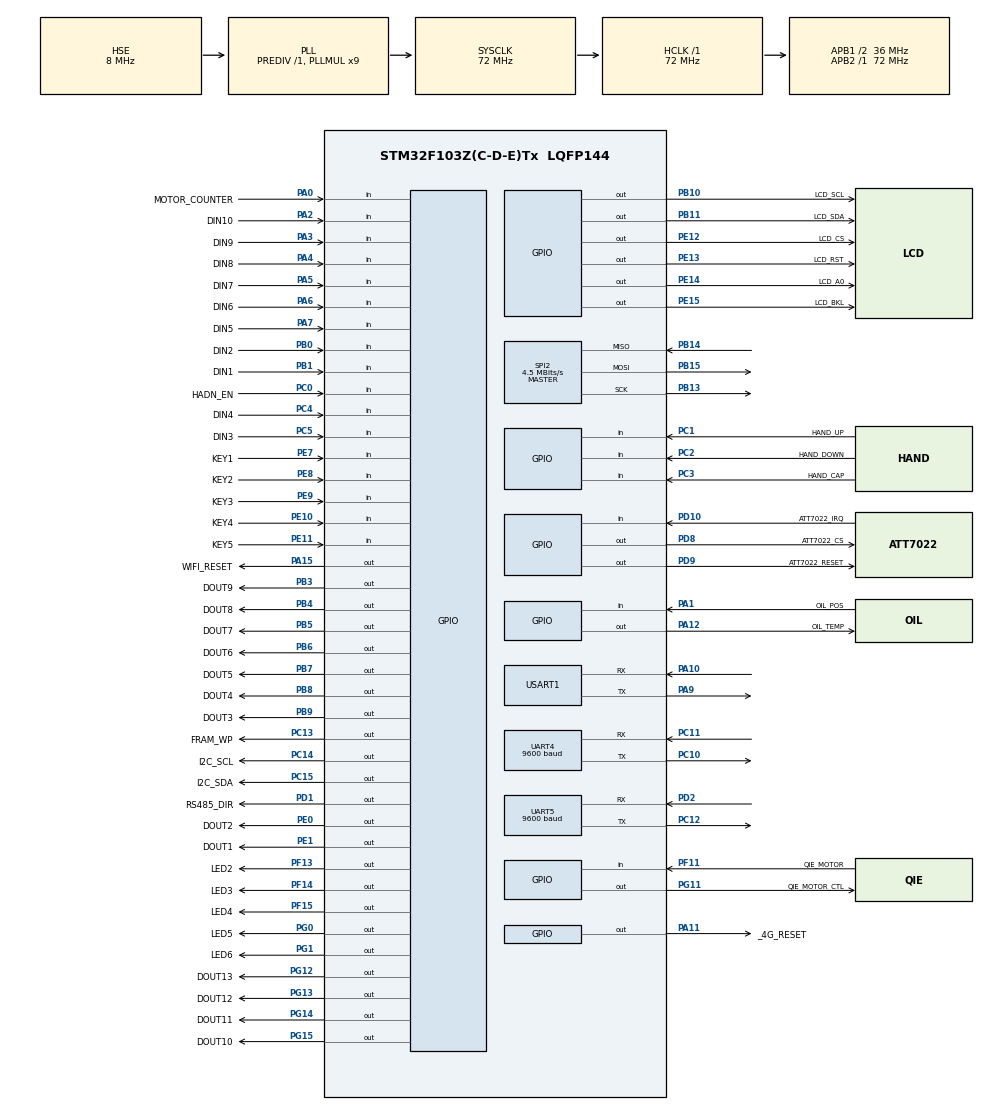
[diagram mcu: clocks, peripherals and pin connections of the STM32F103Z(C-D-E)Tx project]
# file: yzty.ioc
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IWDG.Prescaler=IWDG_PRESCALER_256
Mcu.Family=STM32F1
Mcu.Name=STM32F103Z(C-D-E)Tx
Mcu.Package=LQFP144
NVIC.PriorityGroup=NVIC_PRIORITYGROUP_4
NVIC.UART4_IRQn=true\:0\:0\:false\:false\:true\:true\:true
NVIC.UART5_IRQn=true\:0\:0\:false\:false\:true\:true\:true
NVIC.USART1_IRQn=true\:0\:0\:false\:false\:true\:true\:true
OSC_IN.Mode=HSE-External-Oscillator
OSC_IN.Signal=RCC_OSC_IN
OSC_OUT.Mode=HSE-External-Oscillator
OSC_OUT.Signal=RCC_OSC_OUT
PA0-WKUP.GPIO_Label=MOTOR_COUNTER
PA0-WKUP.Signal=GPIO_Input
PA1.GPIO_Label=OIL_POS
PA1.GPIO_PuPd=GPIO_PULLUP
PA1.Signal=GPIO_Input
PA10.Mode=Asynchronous
PA10.Signal=USART1_RX
PA11.GPIO_Label=_4G_RESET
PA11.PinState=GPIO_PIN_SET
PA11.Signal=GPIO_Output
PA12.GPIO_Label=OIL_TEMP
PA12.GPIO_ModeDefaultOutputPP=GPIO_MODE_OUTPUT_OD
PA12.GPIO_Speed=GPIO_SPEED_FREQ_HIGH
PA12.PinState=GPIO_PIN_SET
PA12.Signal=GPIO_Output
PA13.Mode=Serial_Wire
PA13.Signal=SYS_JTMS-SWDIO
PA14.Mode=Serial_Wire
PA14.Signal=SYS_JTCK-SWCLK
PA15.GPIO_Label=WIFI_RESET
PA15.PinState=GPIO_PIN_SET
PA15.Signal=GPIO_Output
PA2.GPIO_Label=DIN10
PA2.GPIO_PuPd=GPIO_PULLUP
PA2.Signal=GPIO_Input
PA3.GPIO_Label=DIN9
PA3.GPIO_PuPd=GPIO_PULLUP
PA3.Signal=GPIO_Input
PA4.GPIO_Label=DIN8
PA4.GPIO_PuPd=GPIO_PULLUP
PA4.Signal=GPIO_Input
PA5.GPIO_Label=DIN7
PA5.GPIO_PuPd=GPIO_PULLUP
PA5.Signal=GPIO_Input
PA6.GPIO_Label=DIN6
PA6.GPIO_PuPd=GPIO_PULLUP
PA6.Signal=GPIO_Input
PA7.GPIO_Label=DIN5
PA7.GPIO_PuPd=GPIO_PULLUP
PA7.Signal=GPIO_Input
PA9.Mode=Asynchronous
PA9.Signal=USART1_TX
PB0.GPIO_Label=DIN2
PB0.GPIO_PuPd=GPIO_PULLUP
PB0.Signal=GPIO_Input
PB1.GPIO_Label=DIN1
PB1.GPIO_PuPd=GPIO_PULLUP
PB1.Signal=GPIO_Input
PB10.GPIO_Label=LCD_SCL
PB10.GPIO_Speed=GPIO_SPEED_FREQ_HIGH
PB10.PinState=GPIO_PIN_SET
PB10.Signal=GPIO_Output
PB11.GPIO_Label=LCD_SDA
PB11.GPIO_Speed=GPIO_SPEED_FREQ_HIGH
PB11.PinState=GPIO_PIN_SET
PB11.Signal=GPIO_Output
PB13.Mode=Full_Duplex_Master
PB13.Signal=SPI2_SCK
PB14.Mode=Full_Duplex_Master
PB14.Signal=SPI2_MISO
PB15.Mode=Full_Duplex_Master
PB15.Signal=SPI2_MOSI
PB3.GPIO_Label=DOUT9
PB3.PinState=GPIO_PIN_SET
PB3.Signal=GPIO_Output
PB4.GPIO_Label=DOUT8
PB4.PinState=GPIO_PIN_RESET
PB4.Signal=GPIO_Output
PB5.GPIO_Label=DOUT7
PB5.PinState=GPIO_PIN_SET
PB5.Signal=GPIO_Output
PB6.GPIO_Label=DOUT6
PB6.PinState=GPIO_PIN_SET
PB6.Signal=GPIO_Output
PB7.GPIO_Label=DOUT5
PB7.PinState=GPIO_PIN_SET
PB7.Signal=GPIO_Output
PB8.GPIO_Label=DOUT4
PB8.PinState=GPIO_PIN_SET
PB8.Signal=GPIO_Output
PB9.GPIO_Label=DOUT3
PB9.PinState=GPIO_PIN_SET
PB9.Signal=GPIO_Output
PC0.GPIO_Label=HADN_EN
PC0.Signal=GPIO_Input
PC1.GPIO_Label=HAND_UP
PC1.Signal=GPIO_Input
PC10.Mode=Asynchronous
PC10.Signal=UART4_TX
PC11.Mode=Asynchronous
PC11.Signal=UART4_RX
PC12.Mode=Asynchronous
PC12.Signal=UART5_TX
PC13-TAMPER-RTC.GPIO_Label=FRAM_WP
PC13-TAMPER-RTC.PinState=GPIO_PIN_SET
PC13-TAMPER-RTC.Signal=GPIO_Output
PC14-OSC32_IN.GPIO_Label=I2C_SCL
PC14-OSC32_IN.GPIO_ModeDefaultOutputPP=GPIO_MODE_OUTPUT_OD
PC14-OSC32_IN.GPIO_Speed=GPIO_SPEED_FREQ_HIGH
PC14-OSC32_IN.PinState=GPIO_PIN_SET
PC14-OSC32_IN.Signal=GPIO_Output
PC15-OSC32_OUT.GPIO_Label=I2C_SDA
PC15-OSC32_OUT.GPIO_ModeDefaultOutputPP=GPIO_MODE_OUTPUT_OD
PC15-OSC32_OUT.GPIO_Speed=GPIO_SPEED_FREQ_HIGH
PC15-OSC32_OUT.PinState=GPIO_PIN_SET
PC15-OSC32_OUT.Signal=GPIO_Output
PC2.GPIO_Label=HAND_DOWN
PC2.Signal=GPIO_Input
PC3.GPIO_Label=HAND_CAP
PC3.Signal=GPIO_Input
PC4.GPIO_Label=DIN4
PC4.GPIO_PuPd=GPIO_PULLUP
PC4.Signal=GPIO_Input
PC5.GPIO_Label=DIN3
PC5.GPIO_PuPd=GPIO_PULLUP
PC5.Signal=GPIO_Input
PD1.GPIO_Label=RS485_DIR
PD1.PinState=GPIO_PIN_SET
PD1.Signal=GPIO_Output
PD10.GPIO_Label=ATT7022_IRQ
PD10.Signal=GPIO_Input
PD2.Mode=Asynchronous
PD2.Signal=UART5_RX
PD8.GPIO_Label=ATT7022_CS
PD8.PinState=GPIO_PIN_SET
PD8.Signal=GPIO_Output
PD9.GPIO_Label=ATT7022_RESET
PD9.PinState=GPIO_PIN_SET
PD9.Signal=GPIO_Output
PE0.GPIO_Label=DOUT2
PE0.PinState=GPIO_PIN_SET
PE0.Signal=GPIO_Output
PE1.GPIO_Label=DOUT1
PE1.GPIO_Speed=GPIO_SPEED_FREQ_LOW
PE1.PinState=GPIO_PIN_SET
PE1.Signal=GPIO_Output
PE10.GPIO_Label=KEY4
PE10.Signal=GPIO_Input
PE11.GPIO_Label=KEY5
PE11.Signal=GPIO_Input
PE12.GPIO_Label=LCD_CS
PE12.PinState=GPIO_PIN_SET
PE12.Signal=GPIO_Output
PE13.GPIO_Label=LCD_RST
PE13.PinState=GPIO_PIN_SET
PE13.Signal=GPIO_Output
PE14.GPIO_Label=LCD_A0
PE14.PinState=GPIO_PIN_SET
PE14.Signal=GPIO_Output
PE15.GPIO_Label=LCD_BKL
PE15.PinState=GPIO_PIN_SET
PE15.Signal=GPIO_Output
PE7.GPIO_Label=KEY1
PE7.Signal=GPIO_Input
PE8.GPIO_Label=KEY2
PE8.Signal=GPIO_Input
PE9.GPIO_Label=KEY3
PE9.Signal=GPIO_Input
PF11.GPIO_Label=QIE_MOTOR
PF11.Signal=GPIO_Input
PF13.GPIO_Label=LED2
PF13.PinState=GPIO_PIN_SET
PF13.Signal=GPIO_Output
PF14.GPIO_Label=LED3
PF14.PinState=GPIO_PIN_SET
PF14.Signal=GPIO_Output
PF15.GPIO_Label=LED4
PF15.PinState=GPIO_PIN_SET
PF15.Signal=GPIO_Output
PG0.GPIO_Label=LED5
PG0.PinState=GPIO_PIN_SET
PG0.Signal=GPIO_Output
PG1.GPIO_Label=LED6
PG1.PinState=GPIO_PIN_SET
PG1.Signal=GPIO_Output
PG11.GPIO_Label=QIE_MOTOR_CTL
PG11.Signal=GPIO_Output
PG12.GPIO_Label=DOUT13
PG12.PinState=GPIO_PIN_SET
PG12.Signal=GPIO_Output
PG13.GPIO_Label=DOUT12
PG13.PinState=GPIO_PIN_SET
PG13.Signal=GPIO_Output
PG14.GPIO_Label=DOUT11
PG14.PinState=GPIO_PIN_SET
PG14.Signal=GPIO_Output
PG15.GPIO_Label=DOUT10
PG15.PinState=GPIO_PIN_SET
PG15.Signal=GPIO_Output
ProjectManager.HeapSize=0x200
ProjectManager.StackSize=0x400
ProjectManager.TargetToolchain=MDK-ARM V5
RCC.AHBFreq_Value=72000000
RCC.APB1CLKDivider=RCC_HCLK_DIV2
RCC.APB1Freq_Value=36000000
RCC.APB1TimFreq_Value=72000000
RCC.APB2Freq_Value=72000000
RCC.APB2TimFreq_Value=72000000
RCC.HCLKFreq_Value=72000000
RCC.PLLMUL=RCC_PLL_MUL9
RCC.PLLSourceVirtual=RCC_PLLSOURCE_HSE
RCC.SYSCLKFreq_VALUE=72000000
RCC.SYSCLKSource=RCC_SYSCLKSOURCE_PLLCLK
RCC.USBFreq_Value=72000000
SPI2.BaudRatePrescaler=SPI_BAUDRATEPRESCALER_8
SPI2.CLKPhase=SPI_PHASE_2EDGE
SPI2.CalculateBaudRate=4.5 MBits/s
SPI2.Direction=SPI_DIRECTION_2LINES
SPI2.Mode=SPI_MODE_MASTER
SPI2.VirtualType=VM_MASTER
UART4.BaudRate=9600
UART4.VirtualMode=Asynchronous
UART5.BaudRate=9600
UART5.VirtualMode=Asynchronous
USART1.VirtualMode=VM_ASYNC
VP_IWDG_VS_IWDG.Mode=IWDG_Activate
board=custom

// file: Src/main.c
/* USER CODE BEGIN Header */
/**
  ******************************************************************************
  * @file           : main.c
  * @brief          : Main program body
  ******************************************************************************
  * @attention
  *
  * <h2><center>&copy; Copyright (c) 2019 STMicroelectronics.
  * All rights reserved.</center></h2>
  *
  * This software component is licensed by ST under BSD 3-Clause license,
  * the "License"; You may not use this file except in compliance with the
  * License. You may obtain a copy of the License at:
  *                        opensource.org/licenses/BSD-3-Clause
  *
  ******************************************************************************
  */
/* USER CODE END Header */

#include "main.h"
#include "iwdg.h"
#include "spi.h"
#include "usart.h"
#include "gpio.h"

/* USER CODE BEGIN Includes */
#include "task.h"
#include "debug.h"
/* USER CODE END Includes */

void SystemClock_Config(void);

int main(void)
{

  /* MCU Configuration--------------------------------------------------------*/

  /* Reset of all peripherals, Initializes the Flash interface and the Systick. */
  HAL_Init();

  /* Configure the system clock */
  SystemClock_Config();

  /* USER CODE BEGIN SysInit */
  Cap_Gpio_Init();
  /* USER CODE END SysInit */

  /* Initialize all configured peripherals */
  MX_GPIO_Init();
  MX_SPI2_Init();
  MX_UART4_Init();
  MX_UART5_Init();
  MX_USART1_UART_Init();
  MX_IWDG_Init();
  /* USER CODE BEGIN 2 */
  dprintf("AV1.0.0.2 YZTY Start.\r\n");
  if (LOS_OK != LOS_KernelInit())
  {
    dprintf("LOS_KernelInit start failed.\r\n");
  }
  if (LOS_OK != Task_Create())
  {
    dprintf("Task_Create failed.\r\n");
  }
  if (LOS_OK != LOS_Start())
  {
    dprintf("LOS_Start failed.\r\n");
  }
  /* USER CODE END 2 */

  /* Infinite loop */
  while (1)
  {

    /* USER CODE BEGIN 3 */
    dprintf("LOS_TASK failed.\r\n");
  }
  /* USER CODE END 3 */
}

void SystemClock_Config(void)
{
  RCC_OscInitTypeDef RCC_OscInitStruct = {0};
  RCC_ClkInitTypeDef RCC_ClkInitStruct = {0};

  /** Initializes the CPU, AHB and APB busses clocks
  */
  RCC_OscInitStruct.OscillatorType = RCC_OSCILLATORTYPE_LSI|RCC_OSCILLATORTYPE_HSE;
  RCC_OscInitStruct.HSEState = RCC_HSE_ON;
  RCC_OscInitStruct.HSEPredivValue = RCC_HSE_PREDIV_DIV1;
  RCC_OscInitStruct.HSIState = RCC_HSI_ON;
  RCC_OscInitStruct.LSIState = RCC_LSI_ON;
  RCC_OscInitStruct.PLL.PLLState = RCC_PLL_ON;
  RCC_OscInitStruct.PLL.PLLSource = RCC_PLLSOURCE_HSE;
  RCC_OscInitStruct.PLL.PLLMUL = RCC_PLL_MUL9;
  if (HAL_RCC_OscConfig(&RCC_OscInitStruct) != HAL_OK)
  {
    Error_Handler();
  }
  /** Initializes the CPU, AHB and APB busses clocks
  */
  RCC_ClkInitStruct.ClockType = RCC_CLOCKTYPE_HCLK|RCC_CLOCKTYPE_SYSCLK
                              |RCC_CLOCKTYPE_PCLK1|RCC_CLOCKTYPE_PCLK2;
  RCC_ClkInitStruct.SYSCLKSource = RCC_SYSCLKSOURCE_PLLCLK;
  RCC_ClkInitStruct.AHBCLKDivider = RCC_SYSCLK_DIV1;
  RCC_ClkInitStruct.APB1CLKDivider = RCC_HCLK_DIV2;
  RCC_ClkInitStruct.APB2CLKDivider = RCC_HCLK_DIV1;

  if (HAL_RCC_ClockConfig(&RCC_ClkInitStruct, FLASH_LATENCY_2) != HAL_OK)
  {
    Error_Handler();
  }
}

/* USER CODE BEGIN 4 */
/**
  * @brief  UART error callback.
  * @param  huart UART handle.
  * @retval None
  */
void HAL_UART_ErrorCallback(UART_HandleTypeDef *huart)
{
  /* Prevent unused argument(s) compilation warning */
	if(huart->ErrorCode&HAL_UART_ERROR_ORE)
	{
        dprintf("Error_Handler\r\n");
		__HAL_UART_CLEAR_OREFLAG(huart);
	}
  /* NOTE : This function should not be modified, when the callback is needed,
            the HAL_UART_ErrorCallback can be implemented in the user file.
   */
}

/* USER CODE END 4 */

void Error_Handler(void)
{
}

/************************ (C) COPYRIGHT STMicroelectronics *****END OF FILE****/
